# HDSC_HC32F4A0 register map
Vendor: HDSC Co.,Ltd.; Series: ARMCM4; File version: 1.0
CPU: CM4 r0p1, little endian, MPU, FPU, 4 interrupt priority bits
Registers are 32-bit, read-write, reset 0x0 unless marked. A register's access mark holds for its fields unless they carry their own. Offsets are from the block's base; [hi:lo] are bit positions; {n}, {i} and the like mark numbered series; 'fields as' and 'values as' point back to an identical list.

## TMR41
Base 0x40038000
Same registers: TMR42 0x40038400, TMR43 0x40038800
0x02 OCCRUH 16-bit
0x06 OCCRUL 16-bit
0x0A OCCRVH 16-bit
0x0E OCCRVL 16-bit
0x12 OCCRWH 16-bit
0x16 OCCRWL 16-bit
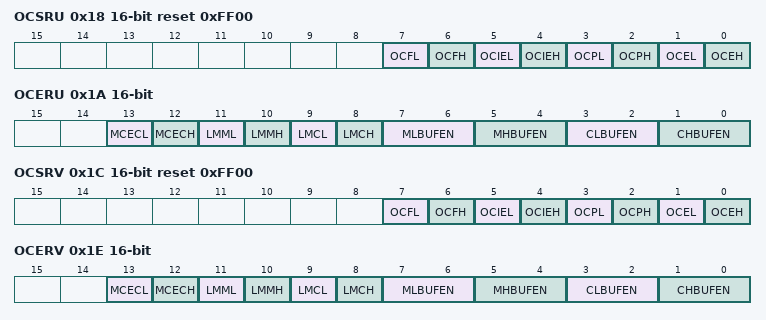
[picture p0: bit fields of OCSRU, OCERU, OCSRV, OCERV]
0x18 OCSRU 16-bit reset 0xFF00
  [7] OCFL, [6] OCFH, [5] OCIEL, [4] OCIEH, [3] OCPL, [2] OCPH, [1] OCEL, [0] OCEH
0x1A OCERU 16-bit
  [13] MCECL, [12] MCECH, [11] LMML, [10] LMMH, [9] LMCL, [8] LMCH, [7:6] MLBUFEN, [5:4] MHBUFEN, [3:2] CLBUFEN, [1:0] CHBUFEN
0x1C OCSRV 16-bit reset 0xFF00
  fields as OCSRU
0x1E OCERV 16-bit
  fields as OCERU
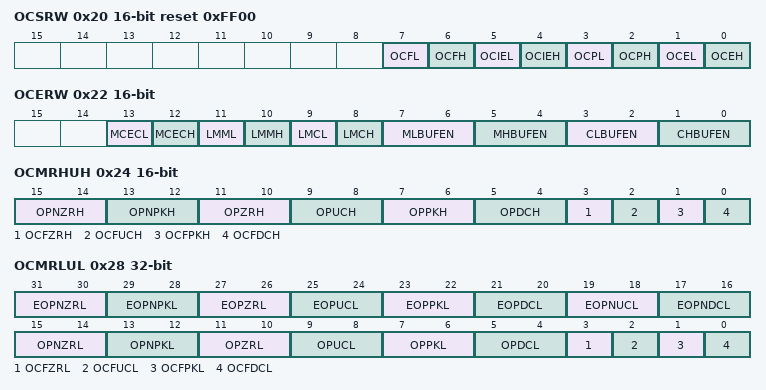
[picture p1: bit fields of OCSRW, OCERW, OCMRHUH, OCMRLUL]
0x20 OCSRW 16-bit reset 0xFF00
  fields as OCSRU
0x22 OCERW 16-bit
  fields as OCERU
0x24 OCMRHUH 16-bit
  [15:14] OPNZRH, [13:12] OPNPKH, [11:10] OPZRH, [9:8] OPUCH, [7:6] OPPKH, [5:4] OPDCH, [3] OCFZRH, [2] OCFUCH, [1] OCFPKH, [0] OCFDCH
0x28 OCMRLUL
  [31:30] EOPNZRL, [29:28] EOPNPKL, [27:26] EOPZRL, [25:24] EOPUCL, [23:22] EOPPKL, [21:20] EOPDCL, [19:18] EOPNUCL, [17:16] EOPNDCL, [15:14] OPNZRL, [13:12] OPNPKL, [11:10] OPZRL, [9:8] OPUCL, [7:6] OPPKL, [5:4] OPDCL, [3] OCFZRL, [2] OCFUCL, [1] OCFPKL, [0] OCFDCL
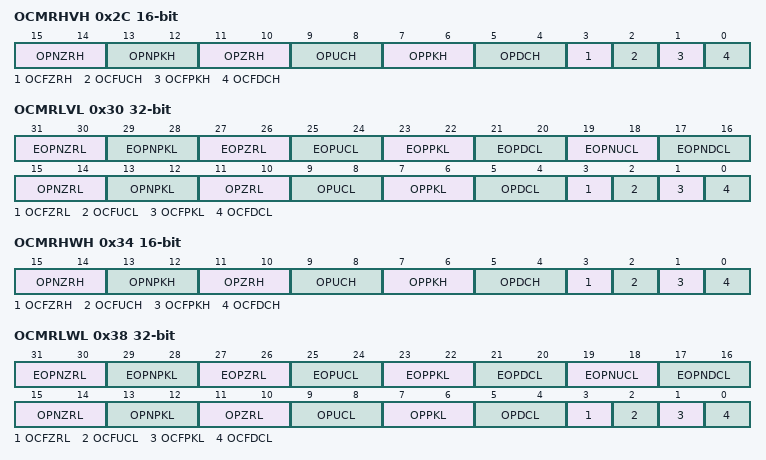
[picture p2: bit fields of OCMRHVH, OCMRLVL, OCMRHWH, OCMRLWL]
0x2C OCMRHVH 16-bit
  fields as OCMRHUH
0x30 OCMRLVL
  fields as OCMRLUL
0x34 OCMRHWH 16-bit
  fields as OCMRHUH
0x38 OCMRLWL
  fields as OCMRLUL
0x42 CPSR 16-bit reset 0xFFFF
0x46 CNTR 16-bit
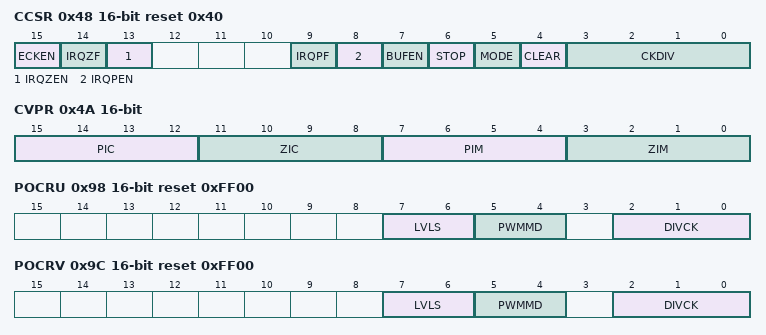
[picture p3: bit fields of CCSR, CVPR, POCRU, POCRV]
0x48 CCSR 16-bit reset 0x40
  [15] ECKEN, [14] IRQZF, [13] IRQZEN, [9] IRQPF, [8] IRQPEN, [7] BUFEN, [6] STOP, [5] MODE, [4] CLEAR, [3:0] CKDIV
0x4A CVPR 16-bit
  [15:12] PIC ro, [11:8] ZIC ro, [7:4] PIM, [3:0] ZIM
0x82 PFSRU 16-bit
0x84 PDARU 16-bit
0x86 PDBRU 16-bit
0x8A PFSRV 16-bit
0x8C PDARV 16-bit
0x8E PDBRV 16-bit
0x92 PFSRW 16-bit
0x94 PDARW 16-bit
0x96 PDBRW 16-bit
0x98 POCRU 16-bit reset 0xFF00
  [7:6] LVLS, [5:4] PWMMD, [2:0] DIVCK
0x9C POCRV 16-bit reset 0xFF00
  [7:6] LVLS, [5:4] PWMMD, [2:0] DIVCK
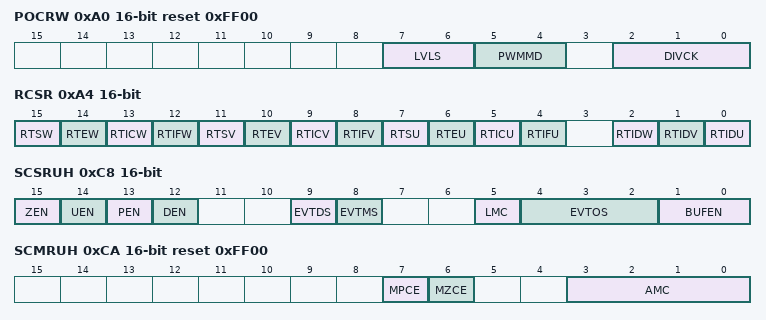
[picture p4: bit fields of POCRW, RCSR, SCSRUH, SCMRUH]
0xA0 POCRW 16-bit reset 0xFF00
  [7:6] LVLS, [5:4] PWMMD, [2:0] DIVCK
0xA4 RCSR 16-bit
  [15] RTSW, [14] RTEW, [13] RTICW, [12] RTIFW ro, [11] RTSV, [10] RTEV, [9] RTICV, [8] RTIFV ro, [7] RTSU, [6] RTEU, [5] RTICU, [4] RTIFU ro, [2] RTIDW, [1] RTIDV, [0] RTIDU
0xB2 SCCRUH 16-bit
0xB6 SCCRUL 16-bit
0xBA SCCRVH 16-bit
0xBE SCCRVL 16-bit
0xC2 SCCRWH 16-bit
0xC6 SCCRWL 16-bit
0xC8 SCSRUH 16-bit
  [15] ZEN, [14] UEN, [13] PEN, [12] DEN, [9] EVTDS, [8] EVTMS, [5] LMC, [4:2] EVTOS, [1:0] BUFEN
0xCA SCMRUH 16-bit reset 0xFF00
  [7] MPCE, [6] MZCE, [3:0] AMC
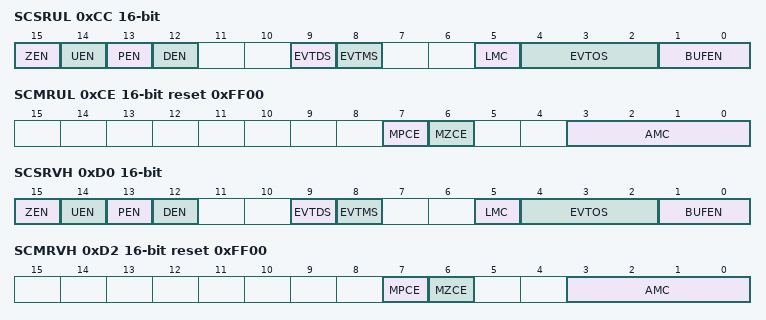
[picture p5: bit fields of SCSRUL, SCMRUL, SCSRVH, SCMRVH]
0xCC SCSRUL 16-bit
  fields as SCSRUH
0xCE SCMRUL 16-bit reset 0xFF00
  [7] MPCE, [6] MZCE, [3:0] AMC
0xD0 SCSRVH 16-bit
  fields as SCSRUH
0xD2 SCMRVH 16-bit reset 0xFF00
  [7] MPCE, [6] MZCE, [3:0] AMC
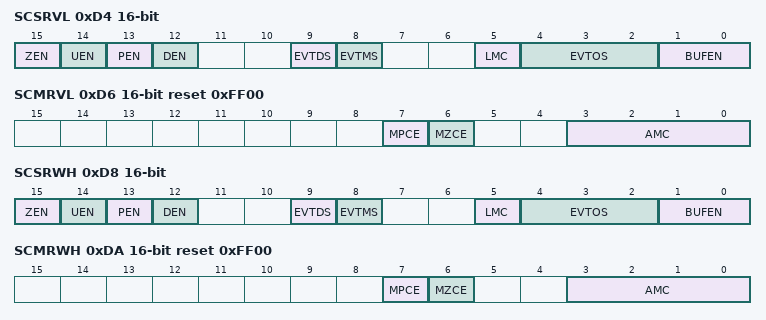
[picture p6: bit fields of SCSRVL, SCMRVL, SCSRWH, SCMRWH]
0xD4 SCSRVL 16-bit
  fields as SCSRUH
0xD6 SCMRVL 16-bit reset 0xFF00
  [7] MPCE, [6] MZCE, [3:0] AMC
0xD8 SCSRWH 16-bit
  fields as SCSRUH
0xDA SCMRWH 16-bit reset 0xFF00
  [7] MPCE, [6] MZCE, [3:0] AMC
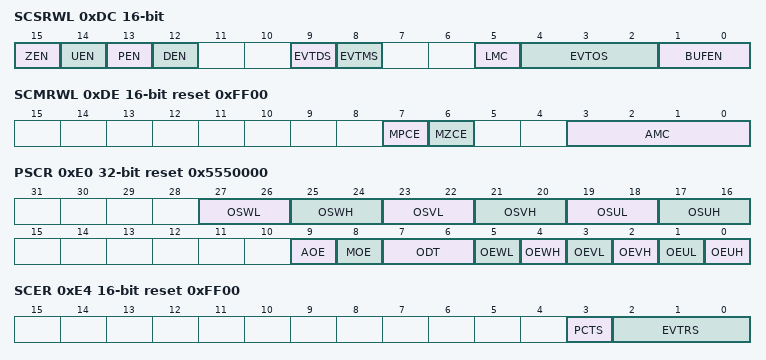
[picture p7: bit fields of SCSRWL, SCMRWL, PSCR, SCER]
0xDC SCSRWL 16-bit
  fields as SCSRUH
0xDE SCMRWL 16-bit reset 0xFF00
  [7] MPCE, [6] MZCE, [3:0] AMC
0xE0 PSCR reset 0x5550000
  [27:26] OSWL, [25:24] OSWH, [23:22] OSVL, [21:20] OSVH, [19:18] OSUL, [17:16] OSUH, [9] AOE, [8] MOE, [7:6] ODT, [5] OEWL, [4] OEWH, [3] OEVL, [2] OEVH, [1] OEUL, [0] OEUH
0xE4 SCER 16-bit reset 0xFF00
  [3] PCTS, [2:0] EVTRS

## TMRA1 — desc TMRA
Base 0x4003A000
Same registers: TMRA{n} {0x40024C00+0x400*n} (n=5..12), TMRA2 0x4003A400, TMRA3 0x4003A800, TMRA4 0x4003AC00
0x00 CNTER
  [15:0] CNT
0x04 PERAR reset 0xFFFF
  [15:0] PER
{0x3C+4i} CMPAR{i} reset 0xFFFF (i=1..4)
  [15:0] CMP
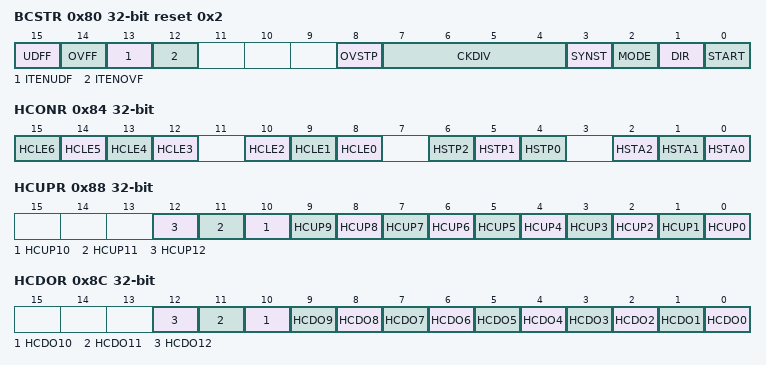
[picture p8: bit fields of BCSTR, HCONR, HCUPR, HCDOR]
0x80 BCSTR reset 0x2
  [15] UDFF, [14] OVFF, [13] ITENUDF, [12] ITENOVF, [8] OVSTP, [7:4] CKDIV, [3] SYNST, [2] MODE, [1] DIR, [0] START
0x84 HCONR
  [n+9] HCLE{n} (n=3..6), [10] HCLE2, [9] HCLE1, [8] HCLE0, [6] HSTP2, [5] HSTP1, [4] HSTP0, [2] HSTA2, [1] HSTA1, [0] HSTA0
0x88 HCUPR
  [n] HCUP{n} (n=0..12)
0x8C HCDOR
  [n] HCDO{n} (n=0..12)
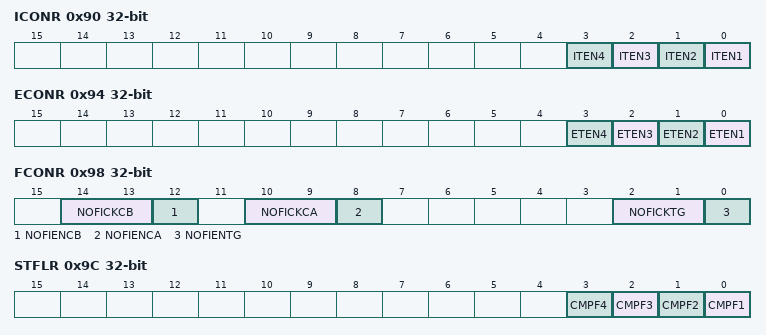
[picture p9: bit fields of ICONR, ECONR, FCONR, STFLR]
0x90 ICONR
  [n-1] ITEN{n} (n=1..4)
0x94 ECONR
  [n-1] ETEN{n} (n=1..4)
0x98 FCONR
  [14:13] NOFICKCB, [12] NOFIENCB, [10:9] NOFICKCA, [8] NOFIENCA, [2:1] NOFICKTG, [0] NOFIENTG
0x9C STFLR
  [n-1] CMPF{n} (n=1..4)
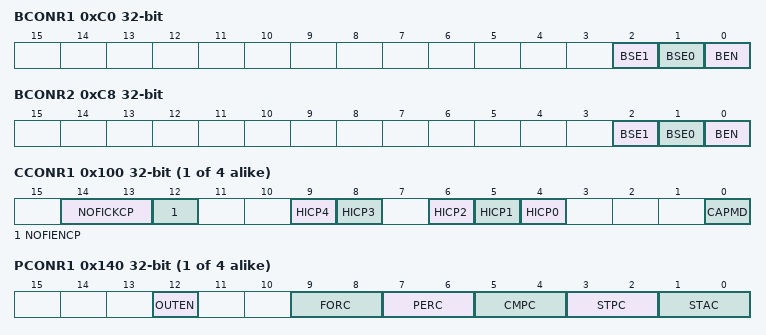
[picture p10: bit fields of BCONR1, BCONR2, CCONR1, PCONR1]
0xC0 BCONR1
  [2] BSE1, [1] BSE0, [0] BEN
0xC8 BCONR2
  [2] BSE1, [1] BSE0, [0] BEN
{0xFC+4i} CCONR{i} (i=1..4)
  [14:13] NOFICKCP, [12] NOFIENCP, [9] HICP4, [8] HICP3, [6] HICP2, [5] HICP1, [4] HICP0, [0] CAPMD
{0x13C+4i} PCONR{i} (i=1..4)
  [12] OUTEN, [9:8] FORC, [7:6] PERC, [5:4] CMPC, [3:2] STPC, [1:0] STAC

## TRNG
Base 0x40042000
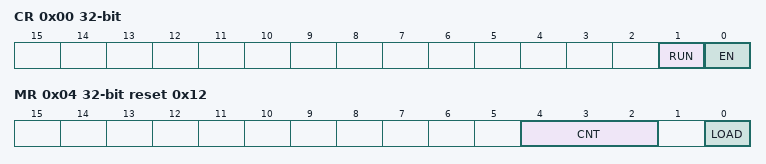
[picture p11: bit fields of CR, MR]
0x00 CR
  [1] RUN, [0] EN
0x04 MR reset 0x12
  [4:2] CNT, [0] LOAD
0x0C DR0 ro reset 0x8000000
0x10 DR1 ro reset 0x8000200

## USART1
Base 0x4001CC00
Same registers: USART2 0x4001D000, USART3 0x4001D400, USART4 0x4001D800, USART6 0x40020C00, USART7 0x40021000, USART8 0x40021400, USART9 0x40021800
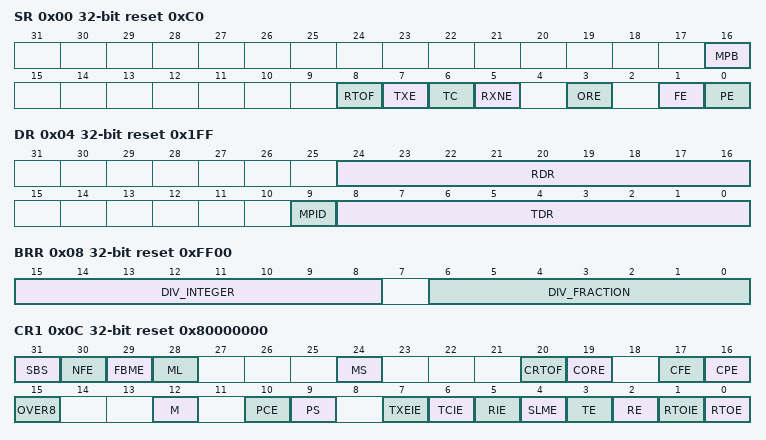
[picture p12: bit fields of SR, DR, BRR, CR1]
0x00 SR ro reset 0xC0
  [16] MPB, [8] RTOF, [7] TXE, [6] TC, [5] RXNE, [3] ORE, [1] FE, [0] PE
0x04 DR reset 0x1FF
  [24:16] RDR, [9] MPID, [8:0] TDR
0x08 BRR reset 0xFF00
  [15:8] DIV_INTEGER, [6:0] DIV_FRACTION
0x0C CR1 reset 0x80000000
  [31] SBS, [30] NFE, [29] FBME, [28] ML, [24] MS, [20] CRTOF wo, [19] CORE wo, [17] CFE wo, [16] CPE wo, [15] OVER8, [12] M, [10] PCE, [9] PS, [7] TXEIE, [6] TCIE, [5] RIE, [4] SLME, [3] TE, [2] RE, [1] RTOIE, [0] RTOE
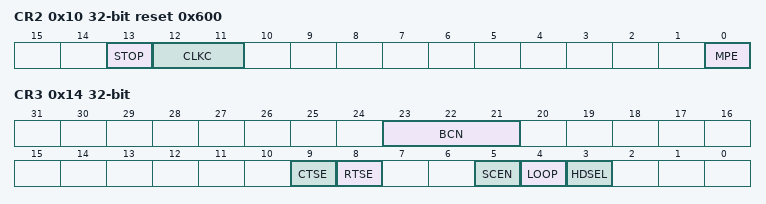
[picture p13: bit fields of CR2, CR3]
0x10 CR2 reset 0x600
  [13] STOP, [12:11] CLKC, [0] MPE
0x14 CR3 (reset mask 0xE00328)
  [23:21] BCN, [9] CTSE, [8] RTSE, [5] SCEN, [4] LOOP, [3] HDSEL
0x18 PR
  [1:0] PSC

## USART10
Base 0x40021C00
Same registers: USART5 0x4001DC00
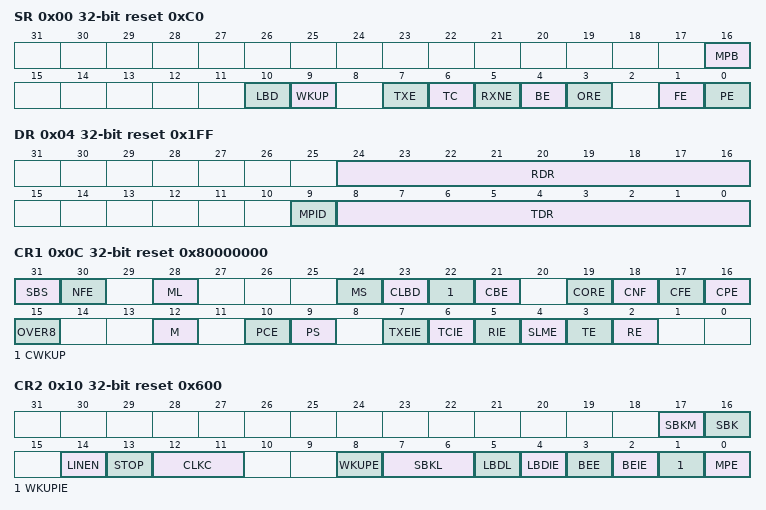
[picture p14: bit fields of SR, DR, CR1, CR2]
0x00 SR ro reset 0xC0
  [16] MPB, [10] LBD, [9] WKUP, [7] TXE, [6] TC, [5] RXNE, [4] BE, [3] ORE, [1] FE, [0] PE
0x04 DR reset 0x1FF
  [24:16] RDR, [9] MPID, [8:0] TDR
0x08 BRR reset 0xFF00
  [15:8] DIV_INTEGER
0x0C CR1 reset 0x80000000
  [31] SBS, [30] NFE, [28] ML, [24] MS, [23] CLBD wo, [22] CWKUP wo, [21] CBE wo, [19] CORE wo, [18] CNF wo, [17] CFE wo, [16] CPE wo, [15] OVER8, [12] M, [10] PCE, [9] PS, [7] TXEIE, [6] TCIE, [5] RIE, [4] SLME, [3] TE, [2] RE
0x10 CR2 reset 0x600
  [17] SBKM, [16] SBK, [14] LINEN, [13] STOP, [12:11] CLKC, [8] WKUPE, [7:6] SBKL, [5] LBDL, [4] LBDIE, [3] BEE, [2] BEIE, [1] WKUPIE, [0] MPE
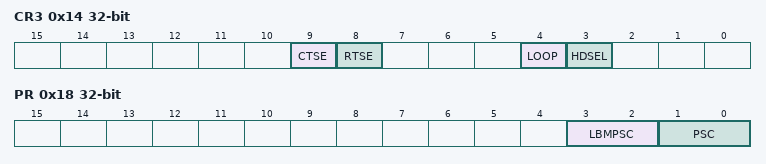
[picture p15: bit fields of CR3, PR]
0x14 CR3
  [9] CTSE, [8] RTSE, [4] LOOP, [3] HDSEL
0x18 PR
  [3:2] LBMPSC, [1:0] PSC
0x1C LBMC
  [15:0] LBMC
